VERSION ""

NS_ :

BS_:

BU_: XXX

CM_ "AUTO-GENERATED by opendbc/car/hondastepper/config.py from config.json or /data/hondastepper/config.json. Do not edit.";

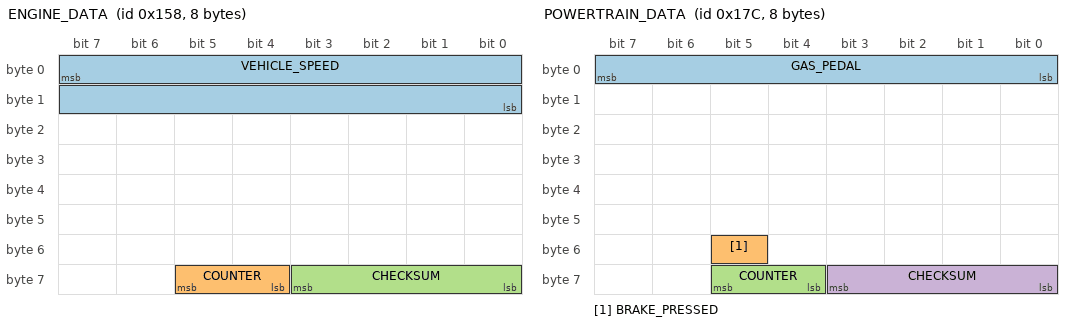
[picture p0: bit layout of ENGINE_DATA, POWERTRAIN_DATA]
BO_ 344 ENGINE_DATA: 8 XXX
 SG_ VEHICLE_SPEED : 7|16@0+ (0.01,0) [0|655.35] "kph" XXX
 SG_ COUNTER : 61|2@0+ (1,0) [0|3] "" XXX
 SG_ CHECKSUM : 59|4@0+ (1,0) [0|15] "" XXX

BO_ 380 POWERTRAIN_DATA: 8 XXX
 SG_ GAS_PEDAL : 7|8@0+ (1,0) [0|255] "" XXX
 SG_ BRAKE_PRESSED : 53|1@0+ (1,0) [0|1] "" XXX
 SG_ COUNTER : 61|2@0+ (1,0) [0|3] "" XXX
 SG_ CHECKSUM : 59|4@0+ (1,0) [0|15] "" XXX

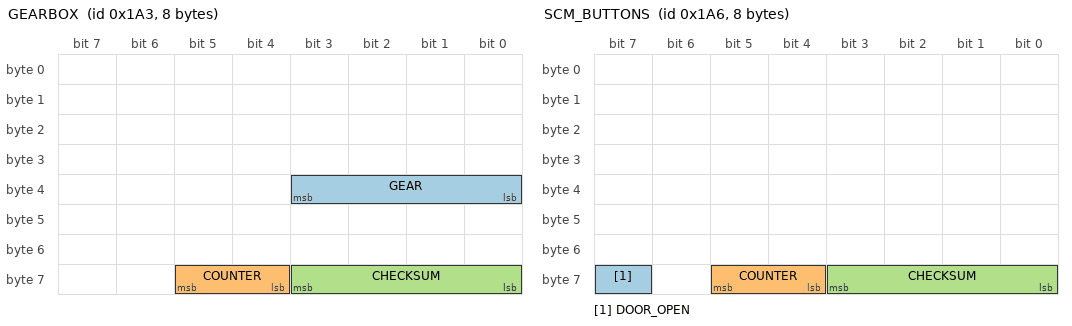
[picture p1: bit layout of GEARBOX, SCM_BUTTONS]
BO_ 419 GEARBOX: 8 XXX
 SG_ GEAR : 35|4@0+ (1,0) [0|15] "" XXX
 SG_ COUNTER : 61|2@0+ (1,0) [0|3] "" XXX
 SG_ CHECKSUM : 59|4@0+ (1,0) [0|15] "" XXX

BO_ 422 SCM_BUTTONS: 8 XXX
 SG_ DOOR_OPEN : 63|1@0+ (1,0) [0|1] "" XXX
 SG_ COUNTER : 61|2@0+ (1,0) [0|3] "" XXX
 SG_ CHECKSUM : 59|4@0+ (1,0) [0|15] "" XXX

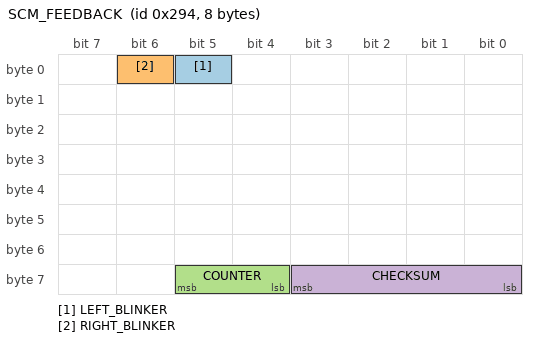
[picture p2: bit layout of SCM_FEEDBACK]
BO_ 660 SCM_FEEDBACK: 8 XXX
 SG_ LEFT_BLINKER : 5|1@0+ (1,0) [0|1] "" XXX
 SG_ RIGHT_BLINKER : 6|1@0+ (1,0) [0|1] "" XXX
 SG_ COUNTER : 61|2@0+ (1,0) [0|3] "" XXX
 SG_ CHECKSUM : 59|4@0+ (1,0) [0|15] "" XXX

VAL_ 419 GEAR 1 "P" 2 "R" 3 "N" 4 "D" 7 "L" 10 "S" ;
